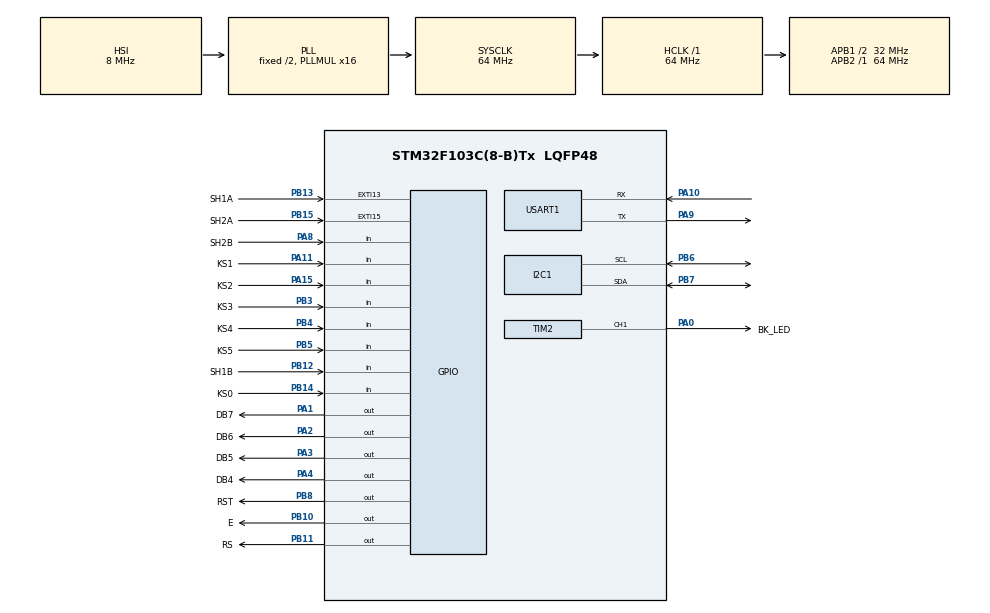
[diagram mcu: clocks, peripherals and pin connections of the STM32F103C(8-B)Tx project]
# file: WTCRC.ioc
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Mcu.Family=STM32F1
Mcu.Name=STM32F103C(8-B)Tx
Mcu.Package=LQFP48
NVIC.EXTI15_10_IRQn=true\:0\:0\:false\:false\:true\:true\:true\:true
NVIC.PriorityGroup=NVIC_PRIORITYGROUP_4
PA0-WKUP.GPIO_Label=BK_LED
PA0-WKUP.Signal=S_TIM2_CH1_ETR
PA1.GPIO_Label=DB7
PA1.GPIO_ModeDefaultOutputPP=GPIO_MODE_OUTPUT_OD
PA1.GPIO_Speed=GPIO_SPEED_FREQ_MEDIUM
PA1.PinState=GPIO_PIN_SET
PA1.Signal=GPIO_Output
PA10.Mode=Asynchronous
PA10.Signal=USART1_RX
PA11.GPIO_Label=KS1
PA11.GPIO_Mode=GPIO_MODE_INPUT
PA11.GPIO_PuPd=GPIO_PULLUP
PA11.Signal=GPIO_Input
PA13.Mode=Serial_Wire
PA13.Signal=SYS_JTMS-SWDIO
PA14.Mode=Serial_Wire
PA14.Signal=SYS_JTCK-SWCLK
PA15.GPIO_Label=KS2
PA15.GPIO_Mode=GPIO_MODE_INPUT
PA15.GPIO_PuPd=GPIO_PULLUP
PA15.Signal=GPIO_Input
PA2.GPIO_Label=DB6
PA2.GPIO_ModeDefaultOutputPP=GPIO_MODE_OUTPUT_OD
PA2.GPIO_Speed=GPIO_SPEED_FREQ_MEDIUM
PA2.PinState=GPIO_PIN_SET
PA2.Signal=GPIO_Output
PA3.GPIO_Label=DB5
PA3.GPIO_ModeDefaultOutputPP=GPIO_MODE_OUTPUT_OD
PA3.GPIO_Speed=GPIO_SPEED_FREQ_MEDIUM
PA3.PinState=GPIO_PIN_SET
PA3.Signal=GPIO_Output
PA4.GPIO_Label=DB4
PA4.GPIO_ModeDefaultOutputPP=GPIO_MODE_OUTPUT_OD
PA4.GPIO_Speed=GPIO_SPEED_FREQ_MEDIUM
PA4.PinState=GPIO_PIN_SET
PA4.Signal=GPIO_Output
PA8.GPIO_Label=SH2B
PA8.GPIO_PuPd=GPIO_PULLUP
PA8.Signal=GPIO_Input
PA9.Mode=Asynchronous
PA9.Signal=USART1_TX
PB10.GPIO_Label=E
PB10.Signal=GPIO_Output
PB11.GPIO_Label=RS
PB11.Signal=GPIO_Output
PB12.GPIO_Label=SH1B
PB12.GPIO_PuPd=GPIO_PULLUP
PB12.Signal=GPIO_Input
PB13.GPIO_Label=SH1A
PB13.GPIO_ModeDefaultEXTI=GPIO_MODE_IT_RISING_FALLING
PB13.GPIO_PuPd=GPIO_PULLUP
PB13.Signal=GPXTI13
PB14.GPIO_Label=KS0
PB14.GPIO_Mode=GPIO_MODE_INPUT
PB14.GPIO_PuPd=GPIO_PULLUP
PB14.Signal=GPIO_Input
PB15.GPIO_Label=SH2A
PB15.GPIO_ModeDefaultEXTI=GPIO_MODE_IT_RISING_FALLING
PB15.GPIO_PuPd=GPIO_PULLUP
PB15.Signal=GPXTI15
PB3.GPIO_Label=KS3
PB3.GPIO_Mode=GPIO_MODE_INPUT
PB3.GPIO_PuPd=GPIO_PULLUP
PB3.Signal=GPIO_Input
PB4.GPIO_Label=KS4
PB4.GPIO_Mode=GPIO_MODE_INPUT
PB4.GPIO_PuPd=GPIO_PULLUP
PB4.Signal=GPIO_Input
PB5.GPIO_Label=KS5
PB5.GPIO_Mode=GPIO_MODE_INPUT
PB5.GPIO_PuPd=GPIO_PULLUP
PB5.Signal=GPIO_Input
PB6.Mode=I2C
PB6.Signal=I2C1_SCL
PB7.Mode=I2C
PB7.Signal=I2C1_SDA
PB8.GPIO_Label=RST
PB8.Signal=GPIO_Output
ProjectManager.HeapSize=0x200
ProjectManager.StackSize=0x400
ProjectManager.TargetToolchain=MDK-ARM V5.32
RCC.AHBFreq_Value=64000000
RCC.APB1CLKDivider=RCC_HCLK_DIV2
RCC.APB1Freq_Value=32000000
RCC.APB1TimFreq_Value=64000000
RCC.APB2Freq_Value=64000000
RCC.APB2TimFreq_Value=64000000
RCC.HCLKFreq_Value=64000000
RCC.PLLMUL=RCC_PLL_MUL16
RCC.SYSCLKFreq_VALUE=64000000
RCC.SYSCLKSource=RCC_SYSCLKSOURCE_PLLCLK
RCC.USBFreq_Value=64000000
SH.S_TIM2_CH1_ETR.0=TIM2_CH1,PWM Generation1 CH1
TIM2.Channel-PWM\ Generation1\ CH1=TIM_CHANNEL_1
TIM2.Period=255
TIM2.Prescaler=999
TIM4.Prescaler=63
USART1.VirtualMode=VM_ASYNC
VP_TIM4_VS_ClockSourceINT.Mode=Internal
board=custom

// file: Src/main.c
/* USER CODE BEGIN Header */
/**
 ******************************************************************************
 * @file           : main.c
 * @brief          : Main program body
 ******************************************************************************
 ** This notice applies to any and all portions of this file
 * that are not between comment pairs USER CODE BEGIN and
 * USER CODE END. Other portions of this file, whether
 * inserted by the user or by software development tools
 * are owned by their respective copyright owners.
 *
 * COPYRIGHT(c) 2019 STMicroelectronics
 *
 * Redistribution and use in source and binary forms, with or without modification,
 * are permitted provided that the following conditions are met:
 *   1. Redistributions of source code must retain the above copyright notice,
 *      this list of conditions and the following disclaimer.
 *   2. Redistributions in binary form must reproduce the above copyright notice,
 *      this list of conditions and the following disclaimer in the documentation
 *      and/or other materials provided with the distribution.
 *   3. Neither the name of STMicroelectronics nor the names of its contributors
 *      may be used to endorse or promote products derived from this software
 *      without specific prior written permission.
 *
 * THIS SOFTWARE IS PROVIDED BY THE COPYRIGHT HOLDERS AND CONTRIBUTORS "AS IS"
 * AND ANY EXPRESS OR IMPLIED WARRANTIES, INCLUDING, BUT NOT LIMITED TO, THE
 * IMPLIED WARRANTIES OF MERCHANTABILITY AND FITNESS FOR A PARTICULAR PURPOSE ARE
 * DISCLAIMED. IN NO EVENT SHALL THE COPYRIGHT HOLDER OR CONTRIBUTORS BE LIABLE
 * FOR ANY DIRECT, INDIRECT, INCIDENTAL, SPECIAL, EXEMPLARY, OR CONSEQUENTIAL
 * DAMAGES (INCLUDING, BUT NOT LIMITED TO, PROCUREMENT OF SUBSTITUTE GOODS OR
 * SERVICES; LOSS OF USE, DATA, OR PROFITS; OR BUSINESS INTERRUPTION) HOWEVER
 * CAUSED AND ON ANY THEORY OF LIABILITY, WHETHER IN CONTRACT, STRICT LIABILITY,
 * OR TORT (INCLUDING NEGLIGENCE OR OTHERWISE) ARISING IN ANY WAY OUT OF THE USE
 * OF THIS SOFTWARE, EVEN IF ADVISED OF THE POSSIBILITY OF SUCH DAMAGE.
 *
 ******************************************************************************
 */
/* USER CODE END Header */
#include "main.h"
/* USER CODE BEGIN Includes */
#include "tuner main.h"
/* USER CODE END Includes */

I2C_HandleTypeDef hi2c1;

TIM_HandleTypeDef htim2;
TIM_HandleTypeDef htim4;

UART_HandleTypeDef huart1;

void SystemClock_Config(void);
static void MX_GPIO_Init(void);
static void MX_TIM2_Init(void);
static void MX_USART1_UART_Init(void);
static void MX_I2C1_Init(void);
static void MX_TIM4_Init(void);

int main(void) {

  /* MCU Configuration--------------------------------------------------------*/

  /* Reset of all peripherals, Initializes the Flash interface and the Systick. */
  HAL_Init();

  /* Configure the system clock */
  SystemClock_Config();

  /* Initialize all configured peripherals */
  MX_GPIO_Init();
  MX_TIM2_Init();
  MX_USART1_UART_Init();
  MX_I2C1_Init();
  MX_TIM4_Init();
  /* USER CODE BEGIN 2 */
  mainTuner();
  /* USER CODE END 2 */

  /* Infinite loop */
  while (1) {

  }
}

void SystemClock_Config(void) {
  RCC_OscInitTypeDef RCC_OscInitStruct = {0};
  RCC_ClkInitTypeDef RCC_ClkInitStruct = {0};

  /** Initializes the RCC Oscillators according to the specified parameters
   * in the RCC_OscInitTypeDef structure.
   */
  RCC_OscInitStruct.OscillatorType = RCC_OSCILLATORTYPE_HSI;
  RCC_OscInitStruct.HSIState = RCC_HSI_ON;
  RCC_OscInitStruct.HSICalibrationValue = RCC_HSICALIBRATION_DEFAULT;
  RCC_OscInitStruct.PLL.PLLState = RCC_PLL_ON;
  RCC_OscInitStruct.PLL.PLLSource = RCC_PLLSOURCE_HSI_DIV2;
  RCC_OscInitStruct.PLL.PLLMUL = RCC_PLL_MUL16;
  if (HAL_RCC_OscConfig(&RCC_OscInitStruct) != HAL_OK) {
    Error_Handler();
  }

  /** Initializes the CPU, AHB and APB buses clocks
   */
  RCC_ClkInitStruct.ClockType = RCC_CLOCKTYPE_HCLK | RCC_CLOCKTYPE_SYSCLK | RCC_CLOCKTYPE_PCLK1 | RCC_CLOCKTYPE_PCLK2;
  RCC_ClkInitStruct.SYSCLKSource = RCC_SYSCLKSOURCE_PLLCLK;
  RCC_ClkInitStruct.AHBCLKDivider = RCC_SYSCLK_DIV1;
  RCC_ClkInitStruct.APB1CLKDivider = RCC_HCLK_DIV2;
  RCC_ClkInitStruct.APB2CLKDivider = RCC_HCLK_DIV1;

  if (HAL_RCC_ClockConfig(&RCC_ClkInitStruct, FLASH_LATENCY_2) != HAL_OK) {
    Error_Handler();
  }
}

static void MX_I2C1_Init(void) {

  hi2c1.Instance = I2C1;
  hi2c1.Init.ClockSpeed = 100000;
  hi2c1.Init.DutyCycle = I2C_DUTYCYCLE_2;
  hi2c1.Init.OwnAddress1 = 0;
  hi2c1.Init.AddressingMode = I2C_ADDRESSINGMODE_7BIT;
  hi2c1.Init.DualAddressMode = I2C_DUALADDRESS_DISABLE;
  hi2c1.Init.OwnAddress2 = 0;
  hi2c1.Init.GeneralCallMode = I2C_GENERALCALL_DISABLE;
  hi2c1.Init.NoStretchMode = I2C_NOSTRETCH_DISABLE;
  if (HAL_I2C_Init(&hi2c1) != HAL_OK) {
    Error_Handler();
  }
}

static void MX_TIM2_Init(void) {

  TIM_MasterConfigTypeDef sMasterConfig = {0};
  TIM_OC_InitTypeDef sConfigOC = {0};

  htim2.Instance = TIM2;
  htim2.Init.Prescaler = 999;
  htim2.Init.CounterMode = TIM_COUNTERMODE_UP;
  htim2.Init.Period = 255;
  htim2.Init.ClockDivision = TIM_CLOCKDIVISION_DIV1;
  htim2.Init.AutoReloadPreload = TIM_AUTORELOAD_PRELOAD_DISABLE;
  if (HAL_TIM_PWM_Init(&htim2) != HAL_OK) {
    Error_Handler();
  }
  sMasterConfig.MasterOutputTrigger = TIM_TRGO_RESET;
  sMasterConfig.MasterSlaveMode = TIM_MASTERSLAVEMODE_DISABLE;
  if (HAL_TIMEx_MasterConfigSynchronization(&htim2, &sMasterConfig) != HAL_OK) {
    Error_Handler();
  }
  sConfigOC.OCMode = TIM_OCMODE_PWM1;
  sConfigOC.Pulse = 0;
  sConfigOC.OCPolarity = TIM_OCPOLARITY_HIGH;
  sConfigOC.OCFastMode = TIM_OCFAST_DISABLE;
  if (HAL_TIM_PWM_ConfigChannel(&htim2, &sConfigOC, TIM_CHANNEL_1) != HAL_OK) {
    Error_Handler();
  }
  HAL_TIM_MspPostInit(&htim2);
}

static void MX_TIM4_Init(void) {

  TIM_ClockConfigTypeDef sClockSourceConfig = {0};
  TIM_MasterConfigTypeDef sMasterConfig = {0};

  htim4.Instance = TIM4;
  htim4.Init.Prescaler = 63;
  htim4.Init.CounterMode = TIM_COUNTERMODE_UP;
  htim4.Init.Period = 65535;
  htim4.Init.ClockDivision = TIM_CLOCKDIVISION_DIV1;
  htim4.Init.AutoReloadPreload = TIM_AUTORELOAD_PRELOAD_DISABLE;
  if (HAL_TIM_Base_Init(&htim4) != HAL_OK) {
    Error_Handler();
  }
  sClockSourceConfig.ClockSource = TIM_CLOCKSOURCE_INTERNAL;
  if (HAL_TIM_ConfigClockSource(&htim4, &sClockSourceConfig) != HAL_OK) {
    Error_Handler();
  }
  sMasterConfig.MasterOutputTrigger = TIM_TRGO_RESET;
  sMasterConfig.MasterSlaveMode = TIM_MASTERSLAVEMODE_DISABLE;
  if (HAL_TIMEx_MasterConfigSynchronization(&htim4, &sMasterConfig) != HAL_OK) {
    Error_Handler();
  }
}

static void MX_USART1_UART_Init(void) {

  huart1.Instance = USART1;
  huart1.Init.BaudRate = 115200;
  huart1.Init.WordLength = UART_WORDLENGTH_8B;
  huart1.Init.StopBits = UART_STOPBITS_1;
  huart1.Init.Parity = UART_PARITY_NONE;
  huart1.Init.Mode = UART_MODE_TX_RX;
  huart1.Init.HwFlowCtl = UART_HWCONTROL_NONE;
  huart1.Init.OverSampling = UART_OVERSAMPLING_16;
  if (HAL_UART_Init(&huart1) != HAL_OK) {
    Error_Handler();
  }
}

static void MX_GPIO_Init(void) {
  GPIO_InitTypeDef GPIO_InitStruct = {0};

  /* GPIO Ports Clock Enable */
  __HAL_RCC_GPIOA_CLK_ENABLE();
  __HAL_RCC_GPIOB_CLK_ENABLE();

  /*Configure GPIO pin Output Level */
  HAL_GPIO_WritePin(GPIOA, DB7_Pin | DB6_Pin | DB5_Pin | DB4_Pin, GPIO_PIN_SET);

  /*Configure GPIO pin Output Level */
  HAL_GPIO_WritePin(GPIOB, E_Pin | RS_Pin | RST_Pin, GPIO_PIN_RESET);

  /*Configure GPIO pins : DB7_Pin DB6_Pin DB5_Pin DB4_Pin */
  GPIO_InitStruct.Pin = DB7_Pin | DB6_Pin | DB5_Pin | DB4_Pin;
  GPIO_InitStruct.Mode = GPIO_MODE_OUTPUT_OD;
  GPIO_InitStruct.Pull = GPIO_NOPULL;
  GPIO_InitStruct.Speed = GPIO_SPEED_FREQ_MEDIUM;
  HAL_GPIO_Init(GPIOA, &GPIO_InitStruct);

  /*Configure GPIO pins : E_Pin RS_Pin RST_Pin */
  GPIO_InitStruct.Pin = E_Pin | RS_Pin | RST_Pin;
  GPIO_InitStruct.Mode = GPIO_MODE_OUTPUT_PP;
  GPIO_InitStruct.Pull = GPIO_NOPULL;
  GPIO_InitStruct.Speed = GPIO_SPEED_FREQ_LOW;
  HAL_GPIO_Init(GPIOB, &GPIO_InitStruct);

  /*Configure GPIO pins : SH1B_Pin KS0_Pin KS3_Pin KS4_Pin
                           KS5_Pin */
  GPIO_InitStruct.Pin = SH1B_Pin | KS0_Pin | KS3_Pin | KS4_Pin | KS5_Pin;
  GPIO_InitStruct.Mode = GPIO_MODE_INPUT;
  GPIO_InitStruct.Pull = GPIO_PULLUP;
  HAL_GPIO_Init(GPIOB, &GPIO_InitStruct);

  /*Configure GPIO pins : SH1A_Pin SH2A_Pin */
  GPIO_InitStruct.Pin = SH1A_Pin | SH2A_Pin;
  GPIO_InitStruct.Mode = GPIO_MODE_IT_RISING_FALLING;
  GPIO_InitStruct.Pull = GPIO_PULLUP;
  HAL_GPIO_Init(GPIOB, &GPIO_InitStruct);

  /*Configure GPIO pins : SH2B_Pin KS1_Pin KS2_Pin */
  GPIO_InitStruct.Pin = SH2B_Pin | KS1_Pin | KS2_Pin;
  GPIO_InitStruct.Mode = GPIO_MODE_INPUT;
  GPIO_InitStruct.Pull = GPIO_PULLUP;
  HAL_GPIO_Init(GPIOA, &GPIO_InitStruct);

  /* EXTI interrupt init*/
  HAL_NVIC_SetPriority(EXTI15_10_IRQn, 0, 0);
  HAL_NVIC_EnableIRQ(EXTI15_10_IRQn);
}

void Error_Handler(void) {
}
